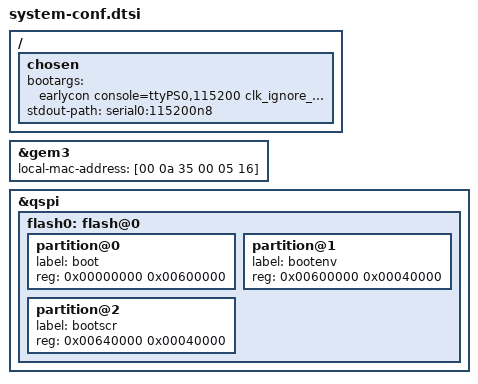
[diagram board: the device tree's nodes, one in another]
/*
 * CAUTION: This file is automatically generated by PetaLinux SDK.
 * DO NOT modify this file
 */


/ {
	chosen {
		bootargs = " earlycon console=ttyPS0,115200 clk_ignore_unused root=/dev/mmcblk1p2 rw rootwait cma=1000M";
		stdout-path = "serial0:115200n8";
	};
};

&gem3 {
	local-mac-address = [00 0a 35 00 05 16];
};

&qspi {
	#address-cells = <1>;
	#size-cells = <0>;
	flash0: flash@0 {
		/delete-node/ partition@0;
		/delete-node/ partition@100000;
		/delete-node/ partition@600000;
		/delete-node/ partition@620000;
		/delete-node/ partition@c00000;
		partition@0 {
			label = "boot";
			reg = <0x00000000 0x00600000>;
		};
		partition@1 {
			label = "bootenv";
			reg = <0x00600000 0x00040000>;
		};
		partition@2 {
			label = "bootscr";
			reg = <0x00640000 0x00040000>;
		};
	};
};

